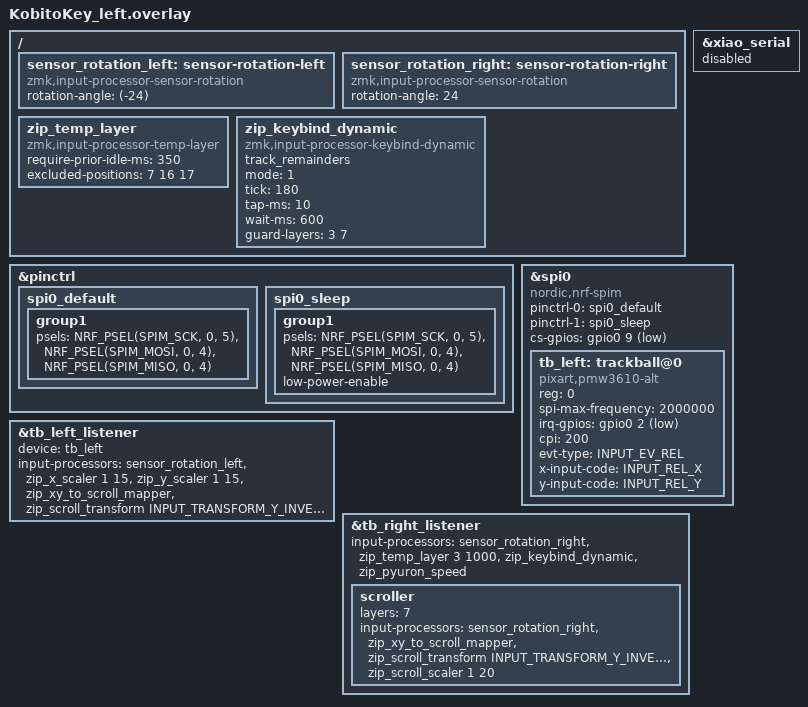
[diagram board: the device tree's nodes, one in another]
#include "kobitokey.dtsi"
#include <zephyr/dt-bindings/input/input-event-codes.h>
#include <input/processors.dtsi>
#include <input/processors/sensor_rotation.dtsi>

&xiao_serial { status = "disabled"; };

&pinctrl {
    spi0_default: spi0_default {
        group1 {
            psels = <NRF_PSEL(SPIM_SCK,  0, 5)>,
                    <NRF_PSEL(SPIM_MOSI, 0, 4)>,
                    <NRF_PSEL(SPIM_MISO, 0, 4)>;
        };
    };
    spi0_sleep: spi0_sleep {
        group1 {
            psels = <NRF_PSEL(SPIM_SCK,  0, 5)>,
                    <NRF_PSEL(SPIM_MOSI, 0, 4)>,
                    <NRF_PSEL(SPIM_MISO, 0, 4)>;
            low-power-enable;
        };
    };
};

&spi0 {
    status = "okay";
    compatible = "nordic,nrf-spim";
    pinctrl-0 = <&spi0_default>;
    pinctrl-1 = <&spi0_sleep>;
    pinctrl-names = "default", "sleep";
    cs-gpios = <&gpio0 9 GPIO_ACTIVE_LOW>;

    tb_left: trackball@0 {
        status = "okay";
        compatible = "pixart,pmw3610-alt";
        reg = <0>;
        spi-max-frequency = <2000000>;
        irq-gpios = <&gpio0 2 (GPIO_ACTIVE_LOW | GPIO_PULL_UP)>;
        cpi = <200>; /* センサー感度 */


        evt-type = <INPUT_EV_REL>;
        x-input-code = <INPUT_REL_X>;
        y-input-code = <INPUT_REL_Y>;
    };
};

/ {
    sensor_rotation_left: sensor-rotation-left {
        compatible = "zmk,input-processor-sensor-rotation";
        status = "okay";
        #input-processor-cells = <0>;
        rotation-angle = <(-24)>;
    };

    sensor_rotation_right: sensor-rotation-right {
        compatible = "zmk,input-processor-sensor-rotation";
        #input-processor-cells = <0>;
        status = "okay";
        rotation-angle = <24>;
    };
};

&tb_left_listener {
    status = "okay";
    device = <&tb_left>;

    input-processors =
            <&sensor_rotation_left>,
            <&zip_x_scaler 1 15>,
            <&zip_y_scaler 1 15>,
            <&zip_xy_to_scroll_mapper>,
            <&zip_scroll_transform INPUT_TRANSFORM_Y_INVERT>;
    };

/ {
  /omit-if-no-ref/ zip_temp_layer: zip_temp_layer {
    compatible = "zmk,input-processor-temp-layer";
    #input-processor-cells = <2>;
    require-prior-idle-ms = <350>; /* キー押下後、何msオートマウスレイヤに入らないようにするか、誤爆防止 */
  };
};

&tb_right_listener {
    status = "okay";

    // 通常時（マウスカーソル移動 ＋ オートマウスレイヤー起動 ＋ ジェスチャー/速度）
    input-processors =
        <&sensor_rotation_right>,
        <&zip_temp_layer 3 1000>,   /* AML: レイヤー3 MOUSE自動 + 滞留時間 */
        <&zip_keybind_dynamic>,     /* ジェスチャー(GEST3=8/GPAGE=9等)を Forge設定でショートカット変換 */
        <&zip_pyuron_speed>;        /* カーソル速度の Forge ライブ調整 */

scroller {
        layers = <7>;  // レイヤー7が有効な時だけ発動
        input-processors = 
            <&sensor_rotation_right>,                           // ← 角度補正はスクロール時も必須！
            <&zip_xy_to_scroll_mapper>,                         // スクロールモードに変更
            <&zip_scroll_transform INPUT_TRANSFORM_Y_INVERT>,
            <&zip_scroll_scaler 1 20>;                           // スクロール量を1/4倍
    };
};

&zip_temp_layer {
    excluded-positions = <
        7
        16
        17
    >;
};

/ {
    // 動的レイヤー対応ジェスチャープロセッサ(Pyuron overhaul と同じ)。
    // 方向→ショートカットの割当は ZMK Forge から実行時設定し NVS 保持(再焼き不要)。
    // guard-layers: 3=MOUSE(AML自動)・7=スクロール は常に素通り(ジェスチャー化しない)。
    zip_keybind_dynamic: zip_keybind_dynamic {
        compatible = "zmk,input-processor-keybind-dynamic";
        #input-processor-cells = <0>;
        track_remainders;
        mode = <1>;
        tick = <180>;
        tap-ms = <10>;
        wait-ms = <600>;
        guard-layers = <3 7>;
    };
};
